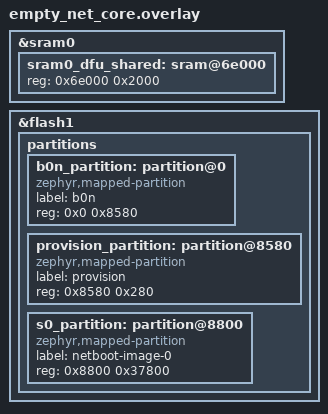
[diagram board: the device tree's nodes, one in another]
/*
 * Copyright (c) 2024 Nordic Semiconductor ASA
 *
 * SPDX-License-Identifier: LicenseRef-Nordic-5-Clause
 */

/delete-node/ &boot_partition;
/delete-node/ &slot0_partition;
/delete-node/ &slot1_partition;
/delete-node/ &storage_partition;

/* Keep sram0_dfu_shared at the same absolute address as on cpuapp (see
 * boards/nrf5340dk_nrf5340_cpuapp_ns.overlay and sysbuild/b0n/boards/
 * nrf5340dk_nrf5340_cpunet.overlay). The default upstream location at
 * offset 0x0 of sram0 (absolute 0x20000000) overlaps with the cpuapp
 * sram0_s (TF-M secure SRAM), which triggers SPU.RAMACCERR on the
 * application core the moment the network core touches it.
 */
/delete-node/ &sram0_dfu_shared;

&sram0 {
	sram0_dfu_shared: sram@6e000 {
		reg = <0x6e000 0x2000>;
	};
};

&flash1 {
	partitions {
		b0n_partition: partition@0 {
			compatible = "zephyr,mapped-partition";
			label = "b0n";
			reg = <0x0 0x8580>;
		};

		provision_partition: partition@8580 {
			compatible = "zephyr,mapped-partition";
			label = "provision";
			reg = <0x8580 0x280>;
		};

		s0_partition: partition@8800 {
			compatible = "zephyr,mapped-partition";
			label = "netboot-image-0";
			reg = <0x8800 0x37800>;
		};
	};
};
